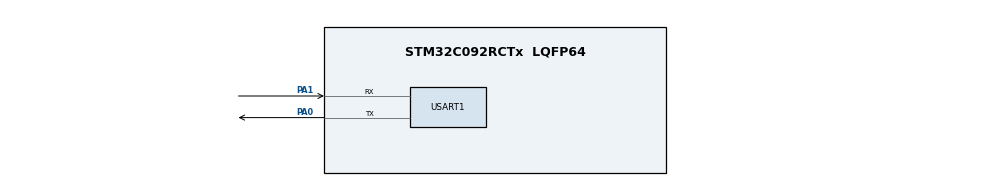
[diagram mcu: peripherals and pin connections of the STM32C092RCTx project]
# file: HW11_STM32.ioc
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Mcu.Family=STM32C0
Mcu.Name=STM32C092RCTx
Mcu.Package=LQFP64
NUCLEO-C092RC.BUTTON=1
NUCLEO-C092RC.LD1=true
NUCLEO-C092RC.LD2=true
NUCLEO-C092RC.VCP=true
NVIC.EXTI4_15_IRQn=true\:0\:0\:false\:false\:true\:false\:true\:true
PA0.Mode=Asynchronous
PA0.Signal=USART1_TX
PA1.Mode=Asynchronous
PA1.Signal=USART1_RX
PA13.GPIO_Label=SWDIO
PA13.Signal=DEBUG_SWDIO
PA14-BOOT0.GPIO_Label=SWCLK
PA14-BOOT0.Signal=DEBUG_SWCLK
PA2.Signal=USART2_TX
PA3.Signal=USART2_RX
PC14-OSCX_IN(PC14).GPIO_Label=OSCX_IN
PC14-OSCX_IN(PC14).Signal=RCC_OSCX_IN
PC15-OSCX_OUT(PC15).GPIO_Label=OSCX_OUT
PC15-OSCX_OUT(PC15).Signal=RCC_OSCX_OUT
PF0-OSC_IN(PF0).GPIO_Label=OSC_IN
PF0-OSC_IN(PF0).Signal=RCC_OSC_IN
PF1-OSC_OUT(PF1).GPIO_Label=OSC_OUT
PF1-OSC_OUT(PF1).Signal=RCC_OSC_OUT
ProjectManager.HeapSize=0x200
ProjectManager.StackSize=0x400
ProjectManager.TargetToolchain=STM32CubeIDE
RCC.ADCFreq_Value=12000000
RCC.AHBFreq_Value=12000000
RCC.CortexFreq_Value=12000000
RCC.EXTERNAL_CLOCK_VALUE=12288000
RCC.HCLKFreq_Value=12000000
RCC.HSE_VALUE=8000000
RCC.HSI_VALUE=48000000
RCC.LSE_VALUE=32768
RCC.SYSCLKFreq_VALUE=12000000
USART1.VirtualMode-Asynchronous=VM_ASYNC
VP_NUCLEO-C092RC_VS_BSP_COMMON.Mode=COMMON
board=NUCLEO-C092RC

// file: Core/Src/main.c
/* USER CODE BEGIN Header */
/**
  ******************************************************************************
  * @file           : main.c
  * @brief          : Main program body
  ******************************************************************************
  * @attention
  *
  * Copyright (c) 2026 STMicroelectronics.
  * All rights reserved.
  *
  * This software is licensed under terms that can be found in the LICENSE file
  * in the root directory of this software component.
  * If no LICENSE file comes with this software, it is provided AS-IS.
  *
  ******************************************************************************
  */
/* USER CODE END Header */
#include "main.h"

/* USER CODE BEGIN Includes */
#include <string.h>
/* USER CODE END Includes */

COM_InitTypeDef BspCOMInit;

UART_HandleTypeDef huart1;

void SystemClock_Config(void);
static void MX_GPIO_Init(void);
static void MX_USART1_UART_Init(void);

int main(void)
{

  /* MCU Configuration--------------------------------------------------------*/

  HAL_Init();

  SystemClock_Config();

  MX_GPIO_Init();
  MX_USART1_UART_Init();

  BSP_LED_Init(LED_GREEN);
  BSP_LED_Init(LED_BLUE);

  BSP_PB_Init(BUTTON_USER, BUTTON_MODE_EXTI);

  BspCOMInit.BaudRate   = 115200;
  BspCOMInit.WordLength = COM_WORDLENGTH_8B;
  BspCOMInit.StopBits   = COM_STOPBITS_1;
  BspCOMInit.Parity     = COM_PARITY_NONE;
  BspCOMInit.HwFlowCtl  = COM_HWCONTROL_NONE;

  if (BSP_COM_Init(COM1, &BspCOMInit) != BSP_ERROR_NONE)
  {
    Error_Handler();
  }

  /* Infinite loop */
  /* USER CODE BEGIN WHILE */
  uint32_t last_send_time = 0;

  while (1)
  {
    /* USER CODE END WHILE */

    /* USER CODE BEGIN 3 */

    if (HAL_GetTick() - last_send_time >= 1000)
    {
      char msg[] = "Hello Pico from STM32\r\n";

      HAL_UART_Transmit(&huart1, (uint8_t*)msg, strlen(msg), HAL_MAX_DELAY);

      printf("STM32 sent: Hello Pico from STM32\r\n");

      last_send_time = HAL_GetTick();
    }

    uint8_t ch;

    if (HAL_UART_Receive(&huart1, &ch, 1, 10) == HAL_OK)
    {
      printf("%c", ch);
    }

    /* USER CODE END 3 */
  }
}

void SystemClock_Config(void)
{
  RCC_OscInitTypeDef RCC_OscInitStruct = {0};
  RCC_ClkInitTypeDef RCC_ClkInitStruct = {0};

  __HAL_FLASH_SET_LATENCY(FLASH_LATENCY_0);

  RCC_OscInitStruct.OscillatorType = RCC_OSCILLATORTYPE_HSI;
  RCC_OscInitStruct.HSIState = RCC_HSI_ON;
  RCC_OscInitStruct.HSIDiv = RCC_HSI_DIV4;
  RCC_OscInitStruct.HSICalibrationValue = RCC_HSICALIBRATION_DEFAULT;

  if (HAL_RCC_OscConfig(&RCC_OscInitStruct) != HAL_OK)
  {
    Error_Handler();
  }

  RCC_ClkInitStruct.ClockType = RCC_CLOCKTYPE_HCLK | RCC_CLOCKTYPE_SYSCLK
                              | RCC_CLOCKTYPE_PCLK1;
  RCC_ClkInitStruct.SYSCLKSource = RCC_SYSCLKSOURCE_HSI;
  RCC_ClkInitStruct.SYSCLKDivider = RCC_SYSCLK_DIV1;
  RCC_ClkInitStruct.AHBCLKDivider = RCC_HCLK_DIV1;
  RCC_ClkInitStruct.APB1CLKDivider = RCC_APB1_DIV1;

  if (HAL_RCC_ClockConfig(&RCC_ClkInitStruct, FLASH_LATENCY_0) != HAL_OK)
  {
    Error_Handler();
  }
}

static void MX_USART1_UART_Init(void)
{

  huart1.Instance = USART1;
  huart1.Init.BaudRate = 115200;
  huart1.Init.WordLength = UART_WORDLENGTH_8B;
  huart1.Init.StopBits = UART_STOPBITS_1;
  huart1.Init.Parity = UART_PARITY_NONE;
  huart1.Init.Mode = UART_MODE_TX_RX;
  huart1.Init.HwFlowCtl = UART_HWCONTROL_NONE;
  huart1.Init.OverSampling = UART_OVERSAMPLING_16;
  huart1.Init.OneBitSampling = UART_ONE_BIT_SAMPLE_DISABLE;
  huart1.Init.ClockPrescaler = UART_PRESCALER_DIV1;
  huart1.AdvancedInit.AdvFeatureInit = UART_ADVFEATURE_NO_INIT;

  if (HAL_UART_Init(&huart1) != HAL_OK)
  {
    Error_Handler();
  }

  if (HAL_UARTEx_SetTxFifoThreshold(&huart1, UART_TXFIFO_THRESHOLD_1_8) != HAL_OK)
  {
    Error_Handler();
  }

  if (HAL_UARTEx_SetRxFifoThreshold(&huart1, UART_RXFIFO_THRESHOLD_1_8) != HAL_OK)
  {
    Error_Handler();
  }

  if (HAL_UARTEx_DisableFifoMode(&huart1) != HAL_OK)
  {
    Error_Handler();
  }

}

static void MX_GPIO_Init(void)
{

  __HAL_RCC_GPIOC_CLK_ENABLE();
  __HAL_RCC_GPIOF_CLK_ENABLE();
  __HAL_RCC_GPIOA_CLK_ENABLE();

}

void Error_Handler(void)
{
  __disable_irq();
  while (1)
  {
  }
}
